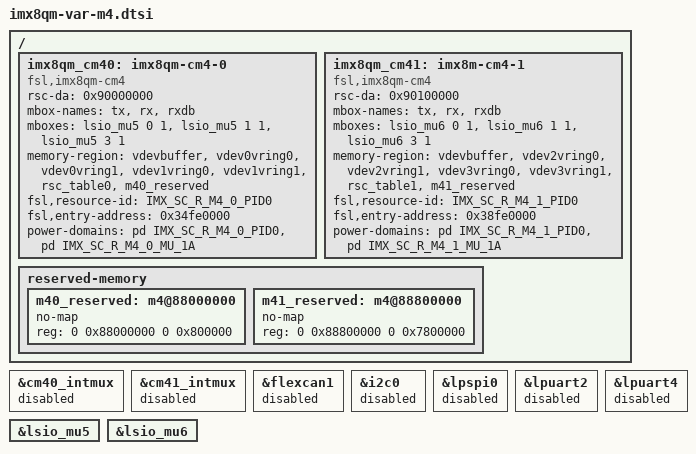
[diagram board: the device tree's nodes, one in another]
// SPDX-License-Identifier: (GPL-2.0+ OR MIT)
/*       
 * Copyright (C) 2026 Variscite Ltd. - https://www.variscite.com/
 *
 */

/ {
	imx8qm_cm40: imx8qm-cm4-0 {
		compatible = "fsl,imx8qm-cm4";
		rsc-da = <0x90000000>;
		mbox-names = "tx", "rx", "rxdb";
		mboxes = <&lsio_mu5 0 1
			  &lsio_mu5 1 1
			  &lsio_mu5 3 1>;
		memory-region = <&vdevbuffer>, <&vdev0vring0>, <&vdev0vring1>,
				<&vdev1vring0>, <&vdev1vring1>, <&rsc_table0>,
				<&m40_reserved>;
		fsl,resource-id = <IMX_SC_R_M4_0_PID0>;
		fsl,entry-address = <0x34fe0000>;
		status = "okay";
		power-domains = <&pd IMX_SC_R_M4_0_PID0>,
				<&pd IMX_SC_R_M4_0_MU_1A>;
	};

	imx8qm_cm41: imx8m-cm4-1 {
		compatible = "fsl,imx8qm-cm4";
		rsc-da = <0x90100000>;
		mbox-names = "tx", "rx", "rxdb";
		mboxes = <&lsio_mu6 0 1
			  &lsio_mu6 1 1
			  &lsio_mu6 3 1>;
		memory-region = <&vdevbuffer>, <&vdev2vring0>, <&vdev2vring1>,
				<&vdev3vring0>, <&vdev3vring1>, <&rsc_table1>,
				<&m41_reserved>;
		fsl,resource-id = <IMX_SC_R_M4_1_PID0>;
		fsl,entry-address = <0x38fe0000>;
		status = "okay";
		power-domains = <&pd IMX_SC_R_M4_1_PID0>,
				<&pd IMX_SC_R_M4_1_MU_1A>;
	};

	reserved-memory {
		#address-cells = <2>;
		#size-cells = <2>;
		ranges;

		/*
		 * reserved-memory layout
		 * 0x8800_0000 ~ 0x8FFF_FFFF is reserved for M4
		 * Shouldn't be used at A core and Linux side.
		 */
		m40_reserved: m4@88000000 {
			no-map;
			reg = <0 0x88000000 0 0x800000>;
		};

		m41_reserved: m4@88800000 {
			no-map;
			reg = <0 0x88800000 0 0x7800000>;
		};
	};

	#include "imx8-ss-cm40.dtsi"
};

&cm40_intmux {
	status = "disabled";
};

&cm41_intmux {
	status = "disabled";
};

&flexcan1 {
	status = "disabled";
};

/* disabling i2c0 the codec wm8904 will be disabled on SOM */
/* disabling i2c0 the capacitive touch will be disabled on SPEAR */
&i2c0 {
	status = "disabled";
};

&lpspi0 {
	status = "disabled";
};

&lpuart2 {
	status = "disabled";
};

&lpuart4 {
	status = "disabled";
};

&lsio_mu5 {
	status = "okay";
};

&lsio_mu6 {
	status = "okay";
};
